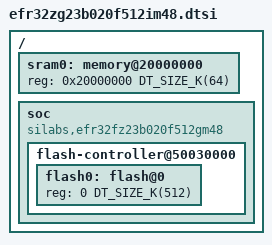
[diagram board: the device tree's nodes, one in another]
/*
 * Copyright (c) 2019 Steven Lemaire
 *
 * SPDX-License-Identifier: Apache-2.0
 */

#include <mem.h>
#include <silabs/efr32zg23.dtsi>

/ {
	sram0: memory@20000000 {
		reg = <0x20000000 DT_SIZE_K(64)>;
	};

	soc {
		compatible = "silabs,efr32fz23b020f512gm48",
					 "silabs,efr32zg23", "silabs,efr32",
					 "simple-bus";

		flash-controller@50030000 {
			flash0: flash@0 {
				reg = <0 DT_SIZE_K(512)>;
			};
		};
	};
};
